# SPC1169 register map
File version: 2022071043481212
CPU: cm4 r1p0, little endian, no MPU, FPU, 4 interrupt priority bits
Registers are 32-bit, read-write, reset 0x0 unless marked. A register's access mark holds for its fields unless they carry their own. Offsets are from the block's base; [hi:lo] are bit positions; {n}, {i} and the like mark numbered series; 'fields as' and 'values as' point back to an identical list.

## ADC
Base 0x40003000
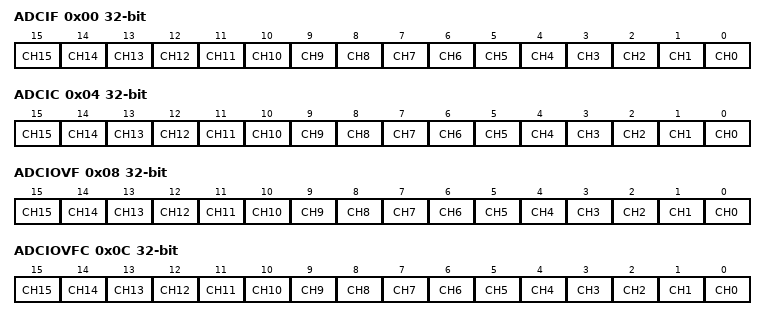
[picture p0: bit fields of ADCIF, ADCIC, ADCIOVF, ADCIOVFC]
0x00 ADCIF ro — ADC Interrupt Flag Register
  [all] fields
    0=NOT_OCCUR (Interrupt does not happen); 1=OCCUR (Interrupt happened)
  [n] CH{n} (n=0..15) — ADC channel {n} interrupt flag
0x04 ADCIC — ADC Interrupt Flag Clear Register
  [15] CH15 — ADC channel 15 interrupt flag clear
    0=NO_EFFECT (Write a 0 has no effect and always read back 0.); 1=CLEAR (Write a 1 clears ADCIF.CH15. This bit is self-cleared.)
  [14] CH14 — ADC channel 14 interrupt flag clear
    0=NO_EFFECT (Write a 0 has no effect and always read back 0.); 1=CLEAR (Write a 1 clears ADCIF.CH14. This bit is self-cleared.)
  [13] CH13 — ADC channel 13 interrupt flag clear
    0=NO_EFFECT (Write a 0 has no effect and always read back 0.); 1=CLEAR (Write a 1 clears ADCIF.CH13. This bit is self-cleared.)
  [12] CH12 — ADC channel 12 interrupt flag clear
    0=NO_EFFECT (Write a 0 has no effect. Always readback 1.); 1=CLEAR (Write a 1 clears ADCIF.CH12. This bit is self-cleared.)
  [n] CH{n} (n=0..11) — ADC channel {n} interrupt flag clear
    0=NO_EFFECT (Write a 0 has no effect and always read back 0.); 1=CLEAR (Write a 1 clears ADCIF.CH{n}. This bit is self-cleared.)
0x08 ADCIOVF ro — ADC Interrupt Overflow Flag Register
  [all] fields
    0=NOT_OCCUR (No overflow); 1=OCCUR (ADC channel interrupt overflow)
  [n] CH{n} (n=0..15) — ADC channel {n} interrupt overflow flag
0x0C ADCIOVFC — ADC Interrupt Overflow Flag Clear Register
  [n] CH{n} (n=0..15) — ADC channel {n} interrupt overflow flag clear
    0=NO_EFFECT (Write a 0 has no effect and always read back 0); 1=CLEAR (Write a 1 clears the ADCIOVF.CH{n}. This bit is self-cleared.)
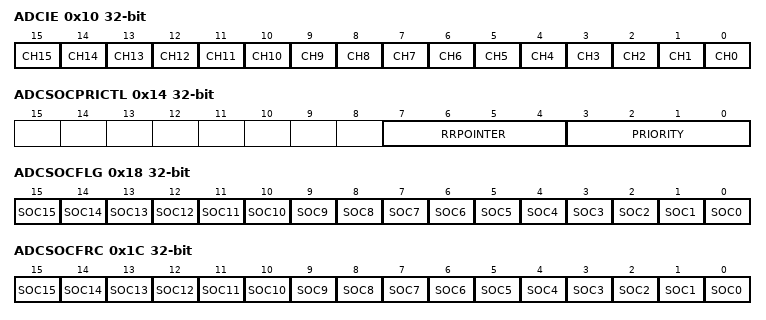
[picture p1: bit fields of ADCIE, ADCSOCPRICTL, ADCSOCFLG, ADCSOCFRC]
0x10 ADCIE — ADC Interrupt Enable Register
  [all] fields
    0=DISABLE (Disable ADC channel interrupt); 1=ENABLE (Enable ADC channel interrupt)
  [n] CH{n} (n=0..15) — ADC channel {n} interrupt enable
0x14 ADCSOCPRICTL — ADC Start of Conversion Priority Control Register
  [7:4] RRPOINTER ro — Round Ring Pointer. Holds the latest SOCx in Round Ring, and determine the next order of conversion.
    {v}=SOC{v} (SOC{v} was the lastest SOC. SOC{v+1} is next one in Round Robin.) (v=0..14); 15=SOC15 (SOC15 was the lastest SOC. SOC0 is next one in Round Robin.)
  [3:0] PRIORITY — SOC (Start of Conversion) Priority. Determineds the cutoff point for priority mode and round arbitration of SOCs
    0=CUTOFF_AT_SOC0 (All SOCs priority follow the rule of round mode); 1=CUTOFF_AT_SOC1 (SOC0 are high priority, SOC1-SOC15 is in round mode); {v}=CUTOFF_AT_SOC{v} (SOC0-SOC{v-1} are high priority, SOC{v}-SOC15 is in round mode) (v=2..14); 15=CUTOFF_AT_SOC15 (SOC0-SOC14 are high priority, SOC15 is in round mode)
0x18 ADCSOCFLG ro — ADC SOC Flag Register
  [n] SOC{n} (n=0..15) — SOC{n} (Start of Conversion) flag
    0=NO_PENDING (No sample pending for SOC{n}); 1=TRIG_RECEIVED (Trigger received and pend sample for SOC{n}. This bit is self-cleared when sample starts.)
0x1C ADCSOCFRC — ADC SOC Force Register
  [n] SOC{n} (n=0..15) — SOC{n} (Start of Conversion) flag force
    0=NO_EFFECT (Write a 0 has no effect and always read back 0); 1=FORCE_CONVERT (Write a 1 forces SOC{n}. This bit is self-cleared.)
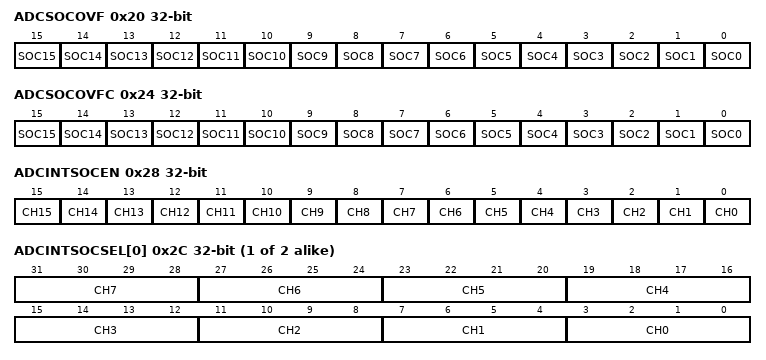
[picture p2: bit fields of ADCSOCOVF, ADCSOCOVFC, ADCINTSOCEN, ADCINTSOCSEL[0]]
0x20 ADCSOCOVF ro — ADC SOC Overflow Register
  [n] SOC{n} (n=0..15) — SOC{n} (Start of Conversion) overflow flag. This indicates an SOC{n} interrupt was generated while an existing SOC{n} interrupt was already pending. This overflow flag can't stop SOC{n} interrupts from being processing. It just show that a trigger was missed.
    0=NOT_OCCUR (No SOC{n} interrupt overflow); 1=OCCUR (SOC{n} interrupt overflow)
0x24 ADCSOCOVFC — ADC SOC Overflow Clear Register
  [all] fields
    0=NO_EFFECT (Write a 0 has no effect and always read back 0.); 1=CLEAR (Write a 1 clears the flag. This bit is self-cleared.)
  [n] SOC{n} (n=10..15) — Clear SOC{n} overflow flag. If this bit receive a request to set from software and hardware try to set respective SOC{n} overflow bit in ADCSOCOVF register simultaneously, then software has priority and ADCSOCOVF register will be cleared.
  [9] SOC9 — Clear SOC9 overflow flag. If this bit receive a request to set from software and hardware try to set respective SOC9 overflow bit in ADCSOCOVF register simultaneously, then hardware has priority and ADCSOCOVF register will be set.
  [8] SOC8 — Clear SOC8 overflow flag. If this bit receive a request to set from software and hardware try to set respective SOC8 overflow bit in ADCSOCOVF register simultaneously, then software has priority and ADCSOCOVF register will be cleared.
  [7] SOC7 — Clear SOC7 overflow flag. If this bit receive a request to set from software and hardware try to set respective SOC7 overflow bit in ADCSOCOVF register simultaneously, then software has priority and ADCSOCOVF register will be cleared.
  [6] SOC6 — Clear SOC6 overflow flag. If this bit receive a request to set from software and hardware try to set respective SOC6 overflow bit in ADCSOCOVF register simultaneously, then hardware has priority and ADCSOCOVF register will be set.
  [5] SOC5 — Clear SOC5 overflow flag. If this bit receive a request to set from software and hardware try to set respective SOC5 overflow bit in ADCSOCOVF register simultaneously, then hardware has priority and ADCSOCOVF register will be set.
  [4] SOC4 — Clear SOC4 overflow flag. If this bit receive a request to set from software and hardware try to set respective SOC4 overflow bit in ADCSOCOVF register simultaneously, then hardware has priority and ADCSOCOVF register will be set.
  [n] SOC{n} (n=0..3) — Clear SOC{n} overflow flag. If this bit receive a request to set from software and hardware try to set respective SOC{n} overflow bit in ADCSOCOVF register simultaneously, then software has priority and ADCSOCOVF register will be cleared.
0x28 ADCINTSOCEN — ADC Interrupt Trigger SOC Enable Register
  [n] CH{n} (n=8..15) — ADC interrupt trigger CH{n} SOC enable
    0=DISABLE (ADCINTSOCSEL1.CH{n} is ignored); 1=ENABLE (ADCCHCTL{n}.TRIGSEL is overriden by ADCINTSOCSEL1.CH{n})
  [n] CH{n} (n=0..7) — ADC interrupt trigger CH{n} SOC enable
    0=DISABLE (ADCINTSOCSEL0.CH{n} is ignored); 1=ENABLE (ADCCHCTL{n}.TRIGSEL is overriden by ADCINTSOCSEL0.CH{n})
{0x2C+4i} ADCINTSOCSEL[{i}] (i=0..1) — ADC Interrupt Trigger SOC Select Register 0
  [4n+3:4n] CH{n} (n=0..7) — ADC CH{n} SOC from which channel interrupt
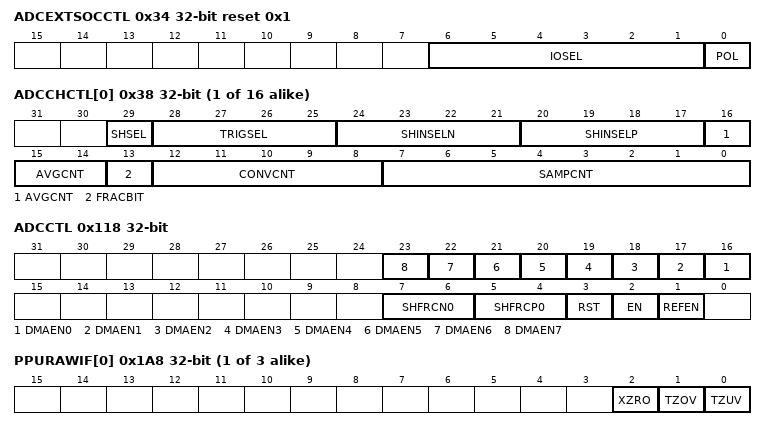
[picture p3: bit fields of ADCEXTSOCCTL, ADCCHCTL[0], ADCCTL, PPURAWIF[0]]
0x34 ADCEXTSOCCTL reset 0x1 — ADC External SOC Input Control Register
  [6:1] IOSEL — GPIO number for EXTSOC
  [0] POL — EXTSOC polarity
    0=ACTIVE_LOW (Active when low); 1=ACTIVE_HIGH (Active when high)
{0x38+4i} ADCCHCTL[{i}] (i=0..15) — ADC Channel Control Register
  [29] SHSEL — SH select
    0=DISABLE (Disable all SH); 1=SH0 (Enable SH0)
  [28:25] TRIGSEL — SOC trigger source, which will set bit in ADCSOCFLG. It can be overridden by ADCINTSOCSEL
    0=SOFTWARE (ADCTRIG0 - Software only); 1=TIMER0 (ADCTRIG1 - Timer 0); 2=TIMER1 (ADCTRIG2 - Timer 1); 3=TIMER2 (ADCTRIG3 - Timer 2); 4=EXTSOC (ADCTRIG4 - EXTSOC); 5=PWM0SOCA (ADCTRIG5 - PWM0SOCA); 6=PWM0SOCB (ADCTRIG6 - PWM0SOCB); 7=PWM0SOCC (ADCTRIG7 - PWM0SOCC); 8=PWM1SOCA (ADCTRIG8 - PWM1SOCA); 9=PWM1SOCB (ADCTRIG9 - PWM1SOCB); 10=PWM1SOCC (ADCTRIG10 - PWM1SOCC); 11=PWM2SOCA (ADCTRIG11 - PWM2SOCA); 12=PWM2SOCB (ADCTRIG12 - PWM2SOCB); 13=PWM2SOCC (ADCTRIG13 - PWM2SOCC); 14=PWM3SOCA (ADCTRIG14 - PWM3SOCA); 15=PWM3SOCB (ADCTRIG15 - PWM3SOCB)
  [24:21] SHINSELN — Select negative input of selected SH
    0=GND (Analog ground); 1=TSENS_N (T-sensor negative output); 2=DPGAN_OUT (Negative output of DPGA); 3=ANA_IN1 (ANA_IN1 pin input); 4=ANA_IN3 (ANA_IN3 pin input); {v}=ANA_IN{v} (ANA_IN{v} pin input) (v=5..8); 9=DAC1 (DAC1 output); 10=DAC2 (DAC2 output); 11=ANA_IN12_PHC (ANA_IN12 pin input / 3-phase common-node sensed signal)
  [20:17] SHINSELP — Select positive input of selected SH
    0=GND (Analog ground); 1=TSENS_P (T-sensor positive output); 2=DPGAP_OUT (Positive output of DPGA); 3=ANA_IN0 (ANA_IN0 pin input); 4=ANA_IN2 (ANA_IN2 pin input); 5=ANA_IN4 (ANA_IN4 pin input); 6=SPGA_OUT (SPGA output); 7=ATEST (ATEST output); 8=DACBUF (DAC buffer output); 9=DAC0 (DAC0 output); 10=VDD12 (Digital 1.2V power); 11=VDD33 (Analog 3.3V power); 12=ANA_IN9_PHU (ANA_IN9 pin input / U-Phase sensed signal); 13=ANA_IN10_PHV (ANA_IN10 pin input / V-Phase sensed signal); 14=ANA_IN11_PHW (ANA_IN11 pin input / W-Phase sensed signal); 15=ANA_IN13_VBATM_DIV (ANA_IN13 pin input / VBATMDIV sensed signal)
  [16:14] AVGCNT — Select average counts for the ADC result
    0=NO_AVG (No average); 1=AVG_2 (Each SOC will trigger 2 consecutive ADC operations and then average); 2=AVG_4 (Each SOC will trigger 4 consecutive ADC operations and then average); 3=AVG_8 (Each SOC will trigger 8 consecutive ADC operations and then average); 4=AVG_16 (Each SOC will trigger 16 consecutive ADC operations and then average); 5=AVG_32 (Each SOC will trigger 32 consecutive ADC operations and then average); 6=AVG_64 (Each SOC will trigger 64 consecutive ADC operations and then average); 7=AVG_128 (Each SOC will trigger 128 consecutive ADC operations and then average)
  [13] FRACBIT — Keep 7 LSBs as fractional part to ADC result due to average
    0=DISABLE (ADC result is a 13-bit integer number); 1=ENABLE (ADC result is 20-bit and the 7 LBSs are the fractional part)
  [12:8] CONVCNT — Conversion window size, which is (CONVCNT + 1) ADC clock cycles
  [7:0] SAMPCNT — Sample window size, which is (SAMPCNT + 1) ADC clock cycles
{0x78+4i} ADCOFFSET[{i}] (i=0..15) — ADC Offset Trim Register [{i}]
  [31:0] VAL — Offset trimming (signed number) for ADCRESULT0. Should be within [-4096, 4095]
{0xB8+4i} ADCGAIN[{i}] (i=0..15) reset 0x8000 — ADC Gain Trim Register [{i}]
  [15:0] VAL — Gain trimming (VAL/32768) for ADCRESULT0
{0xF8+4i} SHOFFSET[{i}] (i=0..0) — ADC SH0 Offset Trim Register
  [31:0] VAL — Offset trimming (signed number) for SH0. Should be within [-4096, 4095]
{0x104+4i} SHGAIN[{i}] (i=0..0) reset 0x8000 — ADC SH0 Gain Trim Register
  [15:0] VAL — Gain trimming (VAL/32768) for SH0
0x110 SHFLG ro — ADC Sample Hold Channel EOC Flag Register
  [0] SHRDY0 — SHRAWCODE0 ready flag
    0=NOT_READY (SHRAWCODE0 not ready); 1=READY (SHRAWCODE0 ready)
0x114 SHFLGCLR — ADC Sample Hold Channel EOC Flag Clear Register
  [0] SHRDY0 — SHRAWCODE0 ready flag clear
    0=NO_EFFECT (Write a 0 has no effect and always read back 0); 1=CLEAR (Write a 1 clears ADCSTS[SHRDY0]. This bit is self-cleared.)
0x118 ADCCTL — ADC Control Register
  [n+16] DMAEN{n} (n=0..7) — ADC result {n} DMA enable
    0=DISABLE; 1=ENABLE
  [7:6] SHFRCN0 — Force SH0 negative input connection
    0=DISABLE; 2=FORCE_LOW (Force SH0 negative input tied low); 3=FORCE_HIGH (Force SH0 negative input tied high)
  [5:4] SHFRCP0 — Force SH0 positive input connection
    0=DISABLE; 2=FORCE_LOW (Force SH0 positve input tied low); 3=FORCE_HIGH (Force SH0 positve input tied high)
  [3] RST — ADC digital finite state machine reset
    0=NO_EFFECT (Write a 0 has no effect and always read back 0); 1=RESET_ADC (Write a 1 reset the ADC digital part. This bit is self-cleared)
  [2] EN — ADC enable
    0=DISABLE; 1=ENABLE
  [1] REFEN — ADC reference enable
    0=DISABLE (Disable ADC); 1=ENABLE (Enable ADC)
{0x11C+4i} SHRAWCODE[{i}] (i=0..0) ro — ADC SH0 Raw Code Register
  [31:0] VAL — Raw code (Signed number from -4096 to 4095) for SH0.
{0x128+4i} ADCRESULT[{i}] (i=0..15) ro — ADC Result Register [{i}]
  [31:0] VAL — ADC result (Signed number from -4096 to 4095)
{0x168+4i} PPURESULT[{i}] (i=0..2) ro — PPU Comparison Result Register [{i}]
  [31:0] VAL — Comparison result with extended sign bit
{0x188+4i} PPUSOCDLY[{i}] (i=0..2) ro — PPU SOC Delay Register [{i}]
  [31:0] VAL — Delay from trigger to execution for SOC selected by PPUCTL[n].SOCSEL
{0x1A8+4i} PPURAWIF[{i}] (i=0..2) ro — PPU Raw Interrupt Flag Register [{i}]
  [2] XZRO — Latched zero-cross event flag
    0=NOT_OCCUR (Zero-cross event does not happen); 1=OCCUR (Zero-cross event happened)
  [1] TZOV — Latched over-voltage event flag
    0=NOT_OCCUR (Over-voltage event does not happen); 1=OCCUR (Over-voltage event happened)
  [0] TZUV — Latched under-voltage event flag
    0=NOT_OCCUR (Under-voltage event does not happen); 1=OCCUR (Under-voltage event happened)
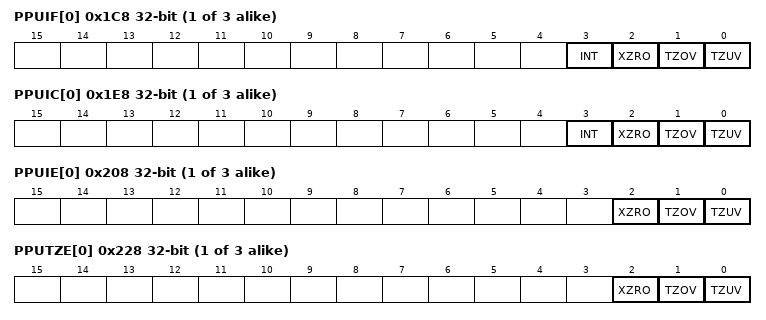
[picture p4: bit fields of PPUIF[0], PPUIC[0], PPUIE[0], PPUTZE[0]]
{0x1C8+4i} PPUIF[{i}] (i=0..2) ro — PPU Interrupt Flag Register [{i}]
  [3] INT — PPU interrupt flag
    0=NOT_OCCUR (PPU interrupt does not happen); 1=OCCUR (PPU interrupt happened and issued to the CPU. Futher interrupt will not be generated until this bit is cleared)
  [2] XZRO — Latched PPU zero-cross interrupt flag
    0=NOT_OCCUR (PPU zero-cross interrupt does not happen); 1=OCCUR (PPU zero-cross interrupt happened. Further event will not trigger interrupt until this bit is cleared)
  [1] TZOV — Latched PPU over-voltage interrupt flag
    0=NOT_OCCUR (PPU over-voltage interrupt does not happen); 1=OCCUR (PPU over-voltage interrupt happened. Further event will not trigger interrupt until this bit is cleared)
  [0] TZUV — Latched PPU under-voltage interrupt flag
    values as TZOV
{0x1E8+4i} PPUIC[{i}] (i=0..2) — PPU Interrupt Clear Register [{i}]
  [3] INT — PPU interrupt flag clear
    0=NO_EFFECT (Write a 0 has no effect and always read back 0); 1=CLEAR (Write a 1 clears the interrupt flag. This bit is self-cleared.)
  [2] XZRO — PPU zero-cross interrupt clear
    0=NO_EFFECT (Write a 0 has no effect and always read back 0); 1=CLEAR (Write a 1 clears the XZRO flag. This bit is self-cleared.)
  [1] TZOV — PPU over-voltage interrupt clear
    0=NO_EFFECT (Write a 0 has no effect and always read back 0); 1=CLEAR (Write a 1 clears the TZOV flag. This bit is self-cleared.)
  [0] TZUV — PPU under-voltage interrupt clear
    0=NO_EFFECT (Write a 0 has no effect and always read back 0); 1=CLEAR (Write a 1 clears the TZUV flag. This bit is self-cleared.)
{0x208+4i} PPUIE[{i}] (i=0..2) — PPU Interrupt Enable Register [{i}]
  [all] fields
    0=DISABLE; 1=ENABLE
  [2] XZRO — Enable zero-cross event as interrupt source
  [1] TZOV — Enable over-voltage event as interrupt source
  [0] TZUV — Enable under-voltage event as interrupt source
{0x228+4i} PPUTZE[{i}] (i=0..2) — PPU Trip-Zone Event Enable Register [{i}]
  [all] fields
    0=DISABLE; 1=ENABLE
  [2] XZRO — Enable zero-cross event as trip-zone event
  [1] TZOV — Enable over-voltage event as trip-zone event
  [0] TZUV — Enable under-voltage event as trip-zone event
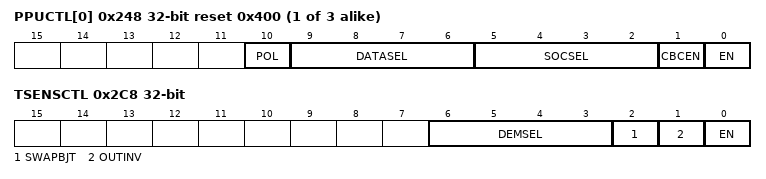
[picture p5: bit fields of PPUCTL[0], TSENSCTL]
{0x248+4i} PPUCTL[{i}] (i=0..2) reset 0x400 — PPU Control Register [{i}]
  [10] POL — Polarity for comparison
    0=REF_MINUS_CODE (PPU result is the reference minus the selected result); 1=CODE_MINUS_REF (PPU result is the selected result minus the reference)
  [9:6] DATASEL — Select the ADC result to compare with the reference
  [5:2] SOCSEL — Select the SOC signal to derive its self PPUSOCDLY[n]
  [1] CBCEN — PPU cycle-by-cycle clear enable
    0=DISABLE (Disable PPU cycle-by-cycle clear); 1=ENABLE (Enable PPU cycle-by-cycle clear)
  [0] EN — PPU enable
    0=DISABLE (Disable PPU); 1=ENABLE (Enable PPU)
{0x268+4i} PPUREF[{i}] (i=0..2) — PPU Reference Register [{i}]
  [31:0] VAL — Reference with extended sign bit. Should be within [-4096, 4095]
{0x288+4i} PPUTHL[{i}] (i=0..2) — PPU Trip-Zone Low-Side Threshold Register [{i}]
  [31:0] VAL — Signed trip-zone threshold within [-8192, 8191]
{0x2A8+4i} PPUTHH[{i}] (i=0..2) — PPU Trip-Zone High-Side Threshold Register [{i}]
  [31:0] VAL — Signed trip-zone threshold within [-8192, 8191]
0x2C8 TSENSCTL — Temperature Sensor Control Register
  [6:3] DEMSEL — Current branch select for dynamic element match
  [2] SWAPBJT
    0=NOT_SWAP (Not swap BJT); 1=SWAP (Swap BJT)
  [1] OUTINV — Invert T-Sensor output 0 and output 1
    0=DISABLE (Normal connect); 1=ENABLE (Invert T-Sensor output 0 and output 1)
  [0] EN — Temperature sensor enable
    0=DISABLE; 1=ENABLE
0x2CC ADCREGKEY reset 0x1ACCE551 — ADC Register Write-Allow Key Register
  [31:0] KEY — Write 0x1ACCE551 to unlock protected ADC registers
